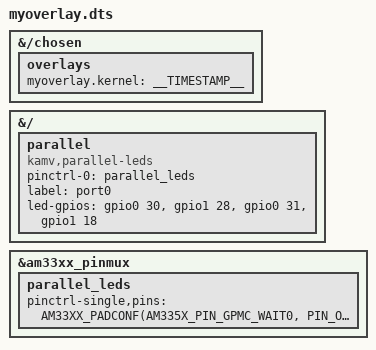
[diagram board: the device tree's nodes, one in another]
/dts-v1/;
/plugin/;

#include <dt-bindings/gpio/gpio.h>
#include <dt-bindings/leds/common.h>
#include <dt-bindings/pinctrl/am33xx.h>

// /proc/device-tree/chosen/overlays
&{/chosen} {
    overlays{
        myoverlay.kernel = __TIMESTAMP__;
    };
};

&{/} {
    parallel {
		pinctrl-names = "default";
		pinctrl-0 = <&parallel_leds>;
        compatible = "kamv,parallel-leds";
        label = "port0";
        led-gpios = <&gpio0 30 GPIO_ACTIVE_HIGH>,
                    <&gpio1 28 GPIO_ACTIVE_HIGH>,
                    <&gpio0 31 GPIO_ACTIVE_HIGH>,
                    <&gpio1 18 GPIO_ACTIVE_HIGH>;
    };
};

// Registeres pins an configuration
&am33xx_pinmux {
    parallel_leds: parallel_leds {
        pinctrl-single,pins = <
            AM33XX_PADCONF(AM335X_PIN_GPMC_WAIT0, PIN_OUTPUT_PULLDOWN, MUX_MODE7)
            AM33XX_PADCONF(AM335X_PIN_GPMC_BEN1, PIN_OUTPUT_PULLDOWN, MUX_MODE7)
            AM33XX_PADCONF(AM335X_PIN_GPMC_WPN, PIN_OUTPUT_PULLDOWN, MUX_MODE7)
            AM33XX_PADCONF(AM335X_PIN_GPMC_A2, PIN_OUTPUT_PULLDOWN, MUX_MODE7)
        >;
    };
};
